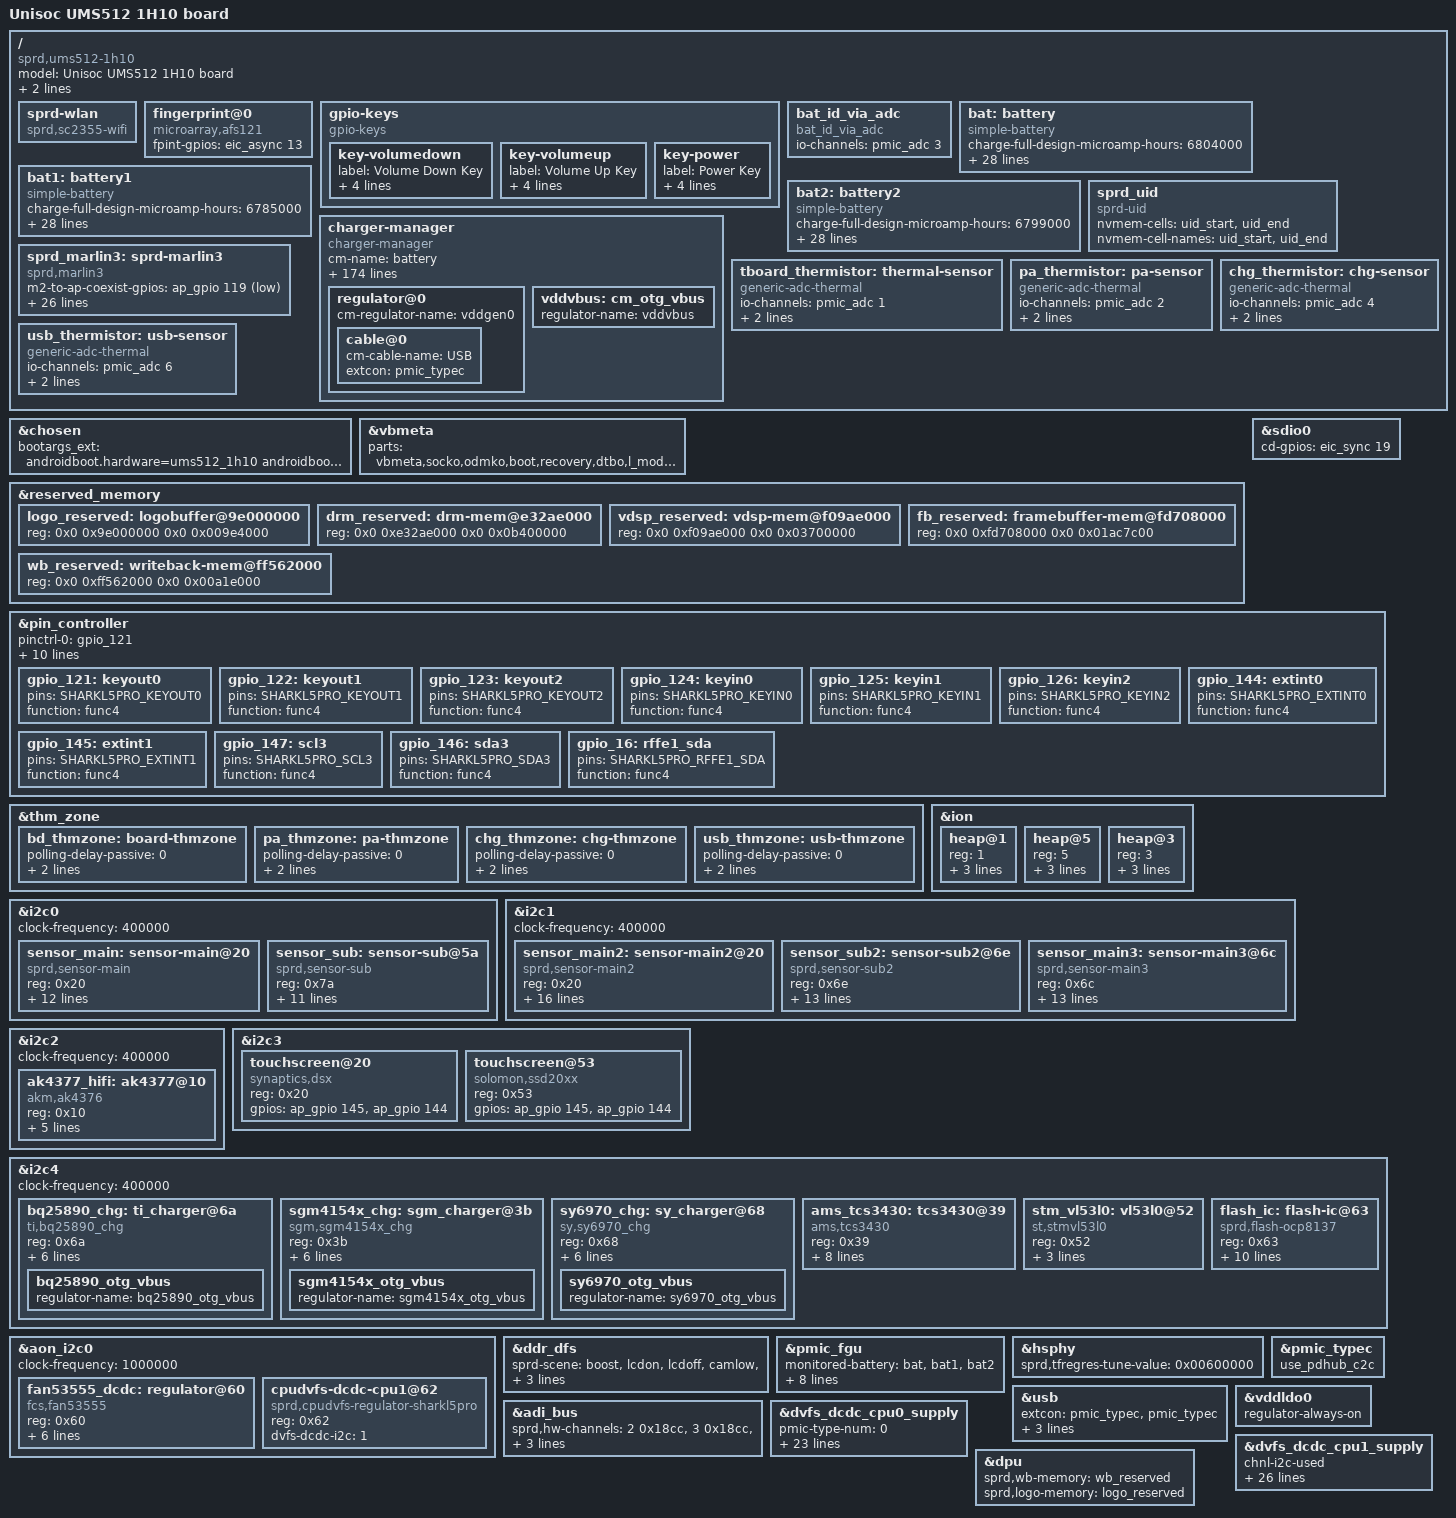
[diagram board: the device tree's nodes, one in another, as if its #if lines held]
/dts-v1/;
/plugin/;

#include <dt-bindings/input/input.h>
#include <dt-bindings/gpio/gpio.h>
#include <dt-bindings/interrupt-controller/arm-gic.h>
#include <dt-bindings/clock/sprd,sharkl5pro-clk.h>
#include <dt-bindings/mfd/sprd,sc2730-regs.h>
#include <dt-bindings/mfd/sprd,sc2730-mask.h>
#include <dt-bindings/wdv/wdv.h>

/ {

	model = "Unisoc UMS512 1H10 board";
	compatible = "sprd,ums512-1h10";
	sprd,sc-id = "ums512 1h10 1000";
	sprd,board_id = <0x1100>; //XX00:base board,XX00~XXFF:customize board

	fragment {
		target-path = "/";
		__overlay__ {
			sprd-wlan {
				compatible = "sprd,sc2355-wifi";
			};

			fingerprint@0 {
				compatible = "microarray,afs121";
				fpint-gpios = <&eic_async 13 0>;
			};

			gpio-keys {
				compatible = "gpio-keys";
				/*Tab A8 code for SR-AX6300-01-23 by fengzhigang at 2021/08/04 start*/
				key-volumedown {
					label = "Volume Down Key";
					linux,code = <KEY_VOLUMEDOWN>;
					gpios = <&pmic_eic 4 GPIO_ACTIVE_HIGH>;
					debounce-interval = <2>;
					wakeup-source;
				};

				key-volumeup {
					label = "Volume Up Key";
					linux,code = <KEY_VOLUMEUP>;
					gpios = <&ap_gpio 125 GPIO_ACTIVE_LOW>;
					debounce-interval = <2>;
					wakeup-source;
				};
				/*Tab A8 code for SR-AX6300-01-23 by fengzhigang at 2021/08/04 end*/
				key-power {
					label = "Power Key";
					linux,code = <KEY_POWER>;
					gpios = <&pmic_eic 1 GPIO_ACTIVE_LOW>;
					debounce-interval = <2>;
					wakeup-source;
				};
			};
			/* Tab A8 code for AX6300DEV-11 by wenyaqi at 20210730 start */
			bat_id_via_adc: bat_id_via_adc {
				compatible = "bat_id_via_adc";
				io-channels = <&pmic_adc 3>;
				io-channel-names = "customer_bat_id";
			};
			/* Tab A8 code for AX6300DEV-11 by wenyaqi at 20210730 end */

			/* Tab A8 code for SR-AX6300-01-106 by zhangyanlong at 20210903 start */
			/* Tab A8 code for SR-AX6300-01-107 by zhangyanlong at 20210830 start */
			/* Tab A8 code for AX6300DEV-11 by wenyaqi at 20210730 start */
			bat: battery {
				compatible = "simple-battery";
				charge-full-design-microamp-hours = <6804000>;
				charge-term-current-microamp = <64000>;
				constant_charge_voltage_max_microvolt = <4400000>;
				factory-internal-resistance-micro-ohms = <120000>;
				voltage-min-design-microvolt = <3456000>;
				ocv-capacity-celsius = <20>;
				ocv-capacity-table-0 = <4354000 100>, <4293000 95>, <4236000 90>,
							<4180000 85>, <4126000 80>, <4075000 75>,
							<4027000 70>, <3985000 65>, <3942000 60>,
							<3887000 55>, <3854000 50>, <3830000 45>,
							<3811000 40>, <3796000 35>, <3782000 30>,
							<3765000 25>, <3746000 20>, <3722000 15>,
							<3693000 10>, <3681000 5>, <3400000 0>;
				voltage-temp-table = <1092000 800>, <984000 850>, <878000 900>,
							  <776000 950>, <679000 1000>, <591000 1050>,
							  <511000 1100>, <441000 1150>, <379000 1200>,
							  <325000 1250>, <278000 1300>, <238000 1350>,
							  <204000 1400>, <175000 1450>, <150000 1500>,
							  <129000 1550>, <112000 1600>, <97000 1650>,
							  <84000 1700>, <73000 1750>, <63000 1800>,
							  <55000 1850>;
				capacity-temp-table = <45 99>, <25 100>, <10 100>, <0 98>, <(-10) 91>, <(-20) 75>;
				resistance-temp-table = <45 88>, <25 100>, <10 156>, <0 541>, <(-10) 683>, <(-20) 756>;
				charge-sdp-current-microamp = <500000 500000>;
				/* Tab A8 code for AX6300DEV-11 by wenyaqi at 20210730 start */
				// charge-dcp-current-microamp = <2000000 3000000>;
				charge-dcp-current-microamp = <2000000 1550000>;
				/* Tab A8 code for AX6300DEV-11 by wenyaqi at 20210730 end */
				charge-cdp-current-microamp = <1150000 1150000>;
				charge-unknown-current-microamp = <500000 500000>;
			};
			/* Tab A8 code for SR-AX6300-01-107 by zhangyanlong at 20210830 end */

			bat1: battery1 {
				compatible = "simple-battery";
				charge-full-design-microamp-hours = <6785000>;
				charge-term-current-microamp = <640000>;
				constant_charge_voltage_max_microvolt = <4400000>;
				factory-internal-resistance-micro-ohms = <116000>;
				voltage-min-design-microvolt = <3456000>;
				ocv-capacity-celsius = <20>;
				ocv-capacity-table-0 = <4357000 100>, <4297000 95>, <4239000 90>,
							<4182000 85>, <4128000 80>, <4076000 75>,
							<4028000 70>, <3985000 65>, <3944000 60>,
							<3885000 55>, <3854000 50>, <3830000 45>,
							<3811000 40>, <3796000 35>, <3783000 30>,
							<3765000 25>, <3746000 20>, <3722000 15>,
							<3693000 10>, <3680000 5>, <3400000 0>;
				voltage-temp-table = <1109000 800>, <998000 850>, <889000 900>,
							  <784000 950>, <685000 1000>, <595000 1050>,
							  <514000 1100>, <442000 1150>, <379000 1200>,
							  <325000 1250>, <270000 1300>, <238000 1350>,
							  <204000 1400>, <175000 1450>, <151000 1500>,
							  <130000 1550>, <112000 1600>, <97000 1650>,
							  <84000 1700>, <73000 1750>, <64000 1800>,
							  <55000 1850>;
				capacity-temp-table = <45 99>, <25 100>, <10 100>, <0 98>, <(-10) 90>, <(-20) 73>;
				resistance-temp-table = <45 67>, <25 100>, <10 371>, <0 609>, <(-10) 718>, <(-20) 794>;
				charge-sdp-current-microamp = <500000 500000>;
				/* Tab A8 code for AX6300DEV-11 by wenyaqi at 20210730 start */
				// charge-dcp-current-microamp = <2000000 3000000>;
				charge-dcp-current-microamp = <2000000 1550000>;
				/* Tab A8 code for AX6300DEV-11 by wenyaqi at 20210730 end */
				charge-cdp-current-microamp = <1150000 1150000>;
				charge-unknown-current-microamp = <500000 500000>;
			};

			/* Tab A8 code for AX6300DEV-114 by zhangyanlong at 20210901 start */
			bat2: battery2 {
				compatible = "simple-battery";
				charge-full-design-microamp-hours = <6799000>;
				charge-term-current-microamp = <640000>;
				constant_charge_voltage_max_microvolt = <4400000>;
				factory-internal-resistance-micro-ohms = <101000>;
				voltage-min-design-microvolt = <3456000>;
				ocv-capacity-celsius = <20>;
				ocv-capacity-table-0 = <4350000 100>, <4293000 95>, <4236000 90>,
							<4180000 85>, <4126000 80>, <4075000 75>,
							<4027000 70>, <3984000 65>, <3941000 60>,
							<3887000 55>, <3854000 50>, <3830000 45>,
							<3810000 40>, <3795000 35>, <3781000 30>,
							<3762000 25>, <3743000 20>, <3719000 15>,
							<3691000 10>, <3680000 5>, <3400000 0>;
				voltage-temp-table = <1109000 800>, <998000 850>, <889000 900>,
							  <784000 950>, <685000 1000>, <595000 1050>,
							  <514000 1100>, <442000 1150>, <379000 1200>,
							  <325000 1250>, <270000 1300>, <238000 1350>,
							  <204000 1400>, <175000 1450>, <151000 1500>,
							  <130000 1550>, <112000 1600>, <97000 1650>,
							  <84000 1700>, <73000 1750>, <64000 1800>,
							  <55000 1850>;
				capacity-temp-table = <45 99>, <25 100>, <10 100>, <0 99>, <(-10) 92>, <(-20) 80>;
				resistance-temp-table = <45 87>, <25 100>, <10 249>, <0 857>, <(-10) 1184>, <(-20) 1311>;
				charge-sdp-current-microamp = <500000 500000>;
				/* Tab A8 code for AX6300DEV-11 by wenyaqi at 20210730 start */
				// charge-dcp-current-microamp = <2000000 3000000>;
				charge-dcp-current-microamp = <2000000 1550000>;
				/* Tab A8 code for AX6300DEV-11 by wenyaqi at 20210730 end */
				charge-cdp-current-microamp = <1150000 1150000>;
				charge-unknown-current-microamp = <500000 500000>;
			};
			/* Tab A8 code for AX6300DEV-114 by zhangyanlong at 20210901 end */
			/* Tab A8 code for SR-AX6300-01-106 by zhangyanlong at 20210903 end */

			charger-manager {
				compatible = "charger-manager";
				cm-name = "battery";
				cm-poll-mode = <2>;
				cm-poll-interval = <15000>;
				cm-battery-stat = <2>;

				/* Tab A8 code for SR-AX6300-01-4 by zhangyanlong at 20210820 start */
				draw-vbus-gpio = <&ap_gpio 137 GPIO_ACTIVE_LOW>;
				io-channels = <&pmic_adc 6>;
				io-channel-names = "customer_usb_ntc";
				/* Tab A8 code for SR-AX6300-01-4 by zhangyanlong at 20210820 end */
				cm-fullbatt-vchkdrop-ms = <30000>;
				/* Tab A8 code for SR-AX6300-01-176 by qiaodan at 20210816 start */
				cm-fullbatt-vchkdrop-volt = <35000>;
				cm-fullbatt-voltage = <4395000>;
				cm-first-fullbatt-current = <280000>;
				cm-fullbatt-current = <180000>;
				/* Tab A8 code for SR-AX6300-01-176 by qiaodan at 20210816 end */
				cm-fullbatt-capacity = <100>;

				/* Tab A8 code for AX6300DEV-11 by wenyaqi at 20210730 start */
				cm-num-power-supplys = <3>;    // numbers of Charger IC
				/* Tab A8 code for AX6300DEV-11 by wenyaqi at 20210730 end */
				cm-chargers = "fan54015_charger";
				/* Tab A8 code for SR-AX6300-01-102 by wenyaqi at 20210808 start */
				cm-power-supplys = "bq25890_charger", "sgm4154x_charger", "sy6970_charger";
				// cm-power-supplys = "fan54015_charger", "sgm4154x_charger", "sy6970_charger";
				/* Tab A8 code for SR-AX6300-01-102 by wenyaqi at 20210808 end */
				cm-fuel-gauge = "sc27xx-fgu";

				/* in deci centigrade */
				/* Tab A8 code for AX6300DEV-11 by wenyaqi at 20210730 start */
				// cm-battery-cold = <200>;
				cm-battery-cold = <0>;
				cm-battery-cold-in-minus;
				// cm-battery-hot = <800>;
				cm-battery-hot = <500>;
				// cm-battery-temp-diff = <100>;
				cm-battery-temp-diff = <30>;
				/* Tab A8 code for AX6300DEV-11 by wenyaqi at 20210730 start */

				/* Allow charging for 6hr */
				cm-charging-max = <21600000>;
				/* recovery charging after stop charging 45min */
				cm-discharging-max = <2700000>;

				/* the interval to feed charger watchdog */
				cm-wdt-interval = <60>;

				/* drop voltage in microVolts to allow shutdown */
				cm-shutdown-voltage = <3100000>;

				/* when 99% of the time is exceeded, it will be forced to 100% */
				cm-tickle-time-out = <1500>;

				/* how much time to allow capacity change */
				cm-one-cap-time = <30>;
				/* Tab A8 code for SR-AX6300-01-102 by wenyaqi at 20210808 start */
				// cm-thermal-zone = "board-thmzone";
				/* Tab A8 code for SR-AX6300-01-102 by wenyaqi at 20210808 end */
				/* when the safe charging voltage is exceeded, stop charging */
				cm-charge-voltage-max = <6500000>;
				/* drop voltage in microVolts to restart charging */
				cm-charge-voltage-drop = <700000>;
				/* Tab A8 code for SR-AX6300-01-176 by qiaodan at 20210816 start */
				cm-dcp-jeita-temp-table = <1000 1030 0 4200000>, <1050 1080 500000 4200000>,
					<1120 1150 1500000 4400000>, <1450 1420 2000000 4400000>, <1500 1470 2000000 4200000>;
				cm-dcp-jeita-temp-table-1 = <1000 1030 0 4200000>, <1050 1080 500000 4200000>,
					<1120 1150 1500000 4400000>, <1450 1420 2000000 4400000>, <1500 1470 2000000 4200000>;
				cm-dcp-jeita-temp-table-2 = <1000 1030 0 4200000>, <1050 1080 500000 4200000>,
					<1120 1150 1500000 4400000>, <1450 1420 2000000 4400000>, <1500 1470 2000000 4200000>;
				cm-sdp-jeita-temp-table = <1000 1030 0 4200000>, <1050 1080 500000 4200000>,
					<1120 1150 540000 4400000>, <1450 1420 540000 4400000>, <1500 1470 540000 4200000>;
				cm-sdp-jeita-temp-table-1 = <1000 1030 0 4200000>, <1050 1080 500000 4200000>,
					<1120 1150 540000 4400000>, <1450 1420 540000 4400000>, <1500 1470 540000 4200000>;
				cm-sdp-jeita-temp-table-2 = <1000 1030 0 4200000>, <1050 1080 500000 4200000>,
					<1120 1150 540000 4400000>, <1450 1420 540000 4400000>, <1500 1470 540000 4200000>;
				cm-cdp-jeita-temp-table = <1000 1030 0 4200000>, <1050 1080 500000 4200000>,
					<1120 1150 1500000 4400000>, <1450 1420 1500000 4400000>, <1500 1470 1500000 4200000>;
				cm-cdp-jeita-temp-table-1 = <1000 1030 0 4200000>, <1050 1080 500000 4200000>,
					<1120 1150 1500000 4400000>, <1450 1420 1500000 4400000>, <1500 1470 1500000 4200000>;
				cm-cdp-jeita-temp-table-2= <1000 1030 0 4200000>, <1050 1080 500000 4200000>,
					<1120 1150 1500000 4400000>, <1450 1420 1500000 4400000>, <1500 1470 1500000 4200000>;
				cm-unknown-jeita-temp-table = <1000 1030 0 4200000>, <1050 1080 500000 4200000>,
					<1120 1150 540000 4400000>, <1450 1420 540000 4400000>, <1500 1470 540000 4200000>;
				cm-unknown-jeita-temp-table-1 = <1000 1030 0 4200000>, <1050 1080 500000 4200000>,
					<1120 1150 540000 4400000>, <1450 1420 540000 4400000>, <1500 1470 540000 4200000>;
				cm-unknown-jeita-temp-table-2 = <1000 1030 0 4200000>, <1050 1080 500000 4200000>,
					<1120 1150 540000 4400000>, <1450 1420 540000 4400000>, <1500 1470 540000 4200000>;
				cm-fchg-jeita-temp-table = <1000 1030 0 4200000>, <1050 1080 500000 4200000>,
					<1120 1150 1500000 4400000>, <1450 1420 2700000 4400000>, <1500 1470 2700000 4200000>;
				cm-fchg-jeita-temp-table-1 = <1000 1030 0 4200000>, <1050 1080 500000 4200000>,
					<1120 1150 1500000 4400000>, <1450 1420 2700000 4400000>, <1500 1470 2700000 4200000>;
				cm-fchg-jeita-temp-table-2 = <1000 1030 0 4200000>, <1050 1080 500000 4200000>,
					<1120 1150 1500000 4400000>, <1450 1420 2700000 4400000>, <1500 1470 2700000 4200000>;
				cm-flash-jeita-temp-table = <1000 1030 0 4200000>, <1050 1080 500000 4200000>,
					<1120 1150 1500000 4400000>, <1450 1420 2000000 4400000>, <1500 1470 2000000 4200000>;
				cm-flash-jeita-temp-table-1 = <1000 1030 0 4200000>, <1050 1080 500000 4200000>,
					<1120 1150 1500000 4400000>, <1450 1420 2000000 4400000>, <1500 1470 2000000 4200000>;
				cm-flash-jeita-temp-table-2 = <1000 1030 0 4200000>, <1050 1080 500000 4200000>,
					<1120 1150 1500000 4400000>, <1450 1420 2000000 4400000>, <1500 1470 2000000 4200000>;
				cm-wl-bpp-jeita-temp-table = <1000 1030 0 4200000>, <1050 1080 500000 4200000>,
					<1120 1150 1000000 4400000>, <1450 1420 1000000 4400000>, <1500 1470 1000000 4200000>;
				cm-wl-bpp-jeita-temp-table-1 = <1000 1030 0 4200000>, <1050 1080 500000 4200000>,
					<1120 1150 1000000 4400000>, <1450 1420 1000000 4400000>, <1500 1470 1000000 4200000>;
				cm-wl-bpp-jeita-temp-table-2 = <1000 1030 0 4200000>, <1050 1080 500000 4200000>,
					<1120 1150 1000000 4400000>, <1450 1420 1000000 4400000>, <1500 1470 1000000 4200000>;
				cm-wl-epp-jeita-temp-table = <1000 1030 0 4200000>, <1050 1080 500000 4200000>,
					<1120 1150 1500000 4400000>, <1450 1420 2000000 4400000>, <1500 1470 2000000 4200000>;
				cm-wl-epp-jeita-temp-table-1 = <1000 1030 0 4200000>, <1050 1080 500000 4200000>,
					<1120 1150 1500000 4400000>, <1450 1420 2000000 4400000>, <1500 1470 2000000 4200000>;
				cm-wl-epp-jeita-temp-table-2 = <1000 1030 0 4200000>, <1050 1080 500000 4200000>,
					<1120 1150 1500000 4400000>, <1450 1420 2000000 4400000>, <1500 1470 2000000 4200000>;
				/* Tab A8 code for SR-AX6300-01-176 by qiaodan at 20210816 end */

				/* Tab A8 code for AX6300DEV-11 by wenyaqi at 20210730 start */
				// monitored-battery = <&bat>;
				monitored-battery = <&bat &bat1 &bat2>; // bat-ATL bat1-SCUD
				/* Tab A8 code for AX6300DEV-11 by wenyaqi at 20210730 end */
				/* Tab A8 code for SR-AX6300-01-142 by qiaodan at 20210901 start */
				ss-batt-aging-enable;
				ss-cv-ranges = <0 299 4400000
						300 399 4368000
						400 699 4352000
						700 999 4304000
						1000 9999 4272000>;
				/* Tab A8 code for SR-AX6300-01-142 by qiaodan at 20210901 end */

				cm-cap-remap-table = <1 2 3>, <2 3 2>, <98 99 2>, <99 100 3>;

				regulator@0 {
					cm-regulator-name = "vddgen0";
					cable@0 {
						cm-cable-name = "USB";
						extcon = <&pmic_typec>;
					};
				};

				/* Tab A8 code for AX6300DEV-11 by wenyaqi at 20210730 start */
				vddvbus: cm_otg_vbus {
					regulator-name = "vddvbus";
				};
				/* Tab A8 code for AX6300DEV-11 by wenyaqi at 20210730 end */
			};

			sprd_uid {
				compatible = "sprd-uid";
				nvmem-cells = <&uid_start>, <&uid_end>;
				nvmem-cell-names = "uid_start", "uid_end";
			};

			sprd_marlin3: sprd-marlin3 {
				compatible = "sprd,marlin3";
				m2-to-ap-coexist-gpios = <&ap_gpio 119 GPIO_ACTIVE_LOW>;
				m2-wakeup-ap-gpios = <&ap_gpio 32 GPIO_ACTIVE_LOW>;
				permit-ap-send-gpios = <&ap_gpio 121 GPIO_ACTIVE_LOW>;
                                /* Tab A8 code for AX6300DEV-27 by lijun at 20210810 start */
				reset-gpios = <&ap_gpio 95 GPIO_ACTIVE_LOW>;
                                /* Tab A8 code for AX6300DEV-27 by lijun at 20210810 end */
				enable-gpios = <&ap_gpio 143 GPIO_ACTIVE_LOW>;
                                /* Tab A8 code for AX6300DEV-27 by lijun at 20210810 start */
				m2-to-ap-irq-gpios = <&ap_gpio 94 GPIO_ACTIVE_LOW>;
                                /* Tab A8 code for AX6300DEV-27 by lijun at 20210810 end */
                                /* Tab A8 code for AX6300DEV-1366 by zhuxiaoming at 20211001 start */
                                xtal-26m-clk-type = "TSX";
                                /* Tab A8 code for AX6300DEV-1366 by zhuxiaoming at 20211001 end */
				avdd12-supply = <&vddwcn>;
				avdd33-supply = <&vddwifipa>;
				dcxo18-supply = <&vddsim2>;
				/* Tab code for SR-AX6300-01-193 by qiaodan at 20210809 start */
				rfcustom-supply = <&vddkpled>;
				/* Tab code for SR-AX6300-01-193 by qiaodan at 20210809 end */
				/* Tab A8 code for P211110-02599 by wangyanjie at 20211213 start */
				sdio-func-def = <3>;
				/* Tab A8 code for P211110-02599 by wangyanjie at 20211213 end */
				clock-names = "clk_32k","source","enable";
				clocks = <&aon_clk CLK_AUX0>,
					 <&ext_32k>,
					 <&aonapb_gate CLK_AUX0_EB>;

				sdhci-name = <&sdio1>;
				sprd,btwf-file-name = "/dev/block/platform/soc/soc:ap-apb/71400000.sdio/by-name/wcnmodem";
				sprd,gnss-file-name = "/dev/block/platform/soc/soc:ap-apb/71400000.sdio/by-name/gnssmodem";
				adma-tx;
				adma-rx;
				/*
				 * bound parameter:
				 * [0]:addr offset, [1]:mask, [2]:unboundval, [3]:boundval
				 */
				avdd12-parent-bound-chip = <REG_ANA_SLP_DCDC_PD_CTRL MASK_ANA_SLP_DCDCGEN1_PD_EN 0x0 MASK_ANA_SLP_DCDCGEN1_PD_EN>;
				avdd12-bound-wbreq = <REG_ANA_LDO_XTL_EN10 MASK_ANA_LDO_VDDWCN_EXT_XTL3_EN 0x0 MASK_ANA_LDO_VDDWCN_EXT_XTL3_EN>;
				avdd33-bound-wbreq = <REG_ANA_LDO_XTL_EN11 MASK_ANA_LDO_VDDWIFIPA_EXT_XTL3_EN 0x0 MASK_ANA_LDO_VDDWIFIPA_EXT_XTL3_EN>;
			};

			tboard_thermistor:thermal-sensor {
				compatible = "generic-adc-thermal";
				#thermal-sensor-cells = <0>;
				io-channels = <&pmic_adc 1>;
				io-channel-names = "sensor-channel";
				temperature-lookup-table = <    (-39742) 1131
								(-29777) 1110
								(-19480) 1074
								(-4679) 983
								10110 838
								24805 654
								44922 413
								54903 316
								64895 238
								74884 178
								84883 133
								94883 100
								104880 75
								114889 57
								124872 43 >;
			};

			/* Tab A8 code for SR-AX6300-01-109 by zhangyanlong at 20210810 start */
			pa_thermistor:pa-sensor {
				compatible = "generic-adc-thermal";
				#thermal-sensor-cells = <0>;
				io-channels = <&pmic_adc 2>;
				io-channel-names = "sensor-channel";
				temperature-lookup-table = <    (-39742) 1131
								(-29777) 1110
								(-19480) 1074
								(-4679) 983
								10110 838
								24805 654
								44922 413
								54903 316
								64895 238
								74884 178
								84883 133
								94883 100
								104880 75
								114889 57
								124872 43 >;
			};

			chg_thermistor:chg-sensor {
				compatible = "generic-adc-thermal";
				#thermal-sensor-cells = <0>;
				io-channels = <&pmic_adc 4>;
				io-channel-names = "sensor-channel";
				temperature-lookup-table = <    (-39742) 1131
								(-29777) 1110
								(-19480) 1074
								(-4679) 983
								10110 838
								24805 654
								44922 413
								54903 316
								64895 238
								74884 178
								84883 133
								94883 100
								104880 75
								114889 57
								124872 43 >;
			};

			usb_thermistor:usb-sensor {
				compatible = "generic-adc-thermal";
				#thermal-sensor-cells = <0>;
				io-channels = <&pmic_adc 6>;
				io-channel-names = "sensor-channel";
				temperature-lookup-table = <    (-39742) 1131
								(-29777) 1110
								(-19480) 1074
								(-4679) 983
								10110 838
								24805 654
								44922 413
								54903 316
								64895 238
								74884 178
								84883 133
								94883 100
								104880 75
								114889 57
								124872 43 >;
			};
			/* Tab A8 code for SR-AX6300-01-109 by zhangyanlong at 20210810 end */
		};
	};
};

&chosen {
	bootargs_ext = "androidboot.hardware=ums512_1h10 androidboot.dtbo_idx=0";
};

&vbmeta {
	parts = "vbmeta,socko,odmko,boot,recovery,dtbo,l_modem,pm_sys,l_ldsp,l_gdsp,l_agdsp";
};

&reserved_memory {

	logo_reserved: logobuffer@9e000000{
		reg = <0x0 0x9e000000 0x0 0x009e4000>;
	};

#ifdef BSP_KERNEL_CONFIG_WIDEVINE_L1
	drm_reserved: drm-mem@e32ae000 {
                /*Tab A8 code for P210929-01927 by ZhangLirong at 2021/10/11 start*/
		reg = <0x0 0xe32ae000 0x0 0x0b400000>;
                /*Tab A8 code for P210929-01927 by ZhangLirong at 2021/10/11 end*/
	};
#endif

/* HS03 code for SR-SL6215-01-755 by bianxiaoqiang at 2021/10/26 start */
/*
	fd_reserved: faceid-mem@efaae000 {
		reg = <0x0 0xefaae000 0x0 0x00500000>;
	};
*/
/* HS03 code for SR-SL6215-01-755 by bianxiaoqiang at 2021/10/26 end */

	vdsp_reserved: vdsp-mem@f09ae000 {
		reg = <0x0 0xf09ae000 0x0 0x03700000>;
	};
/*
	gpu_reserved: gpu-mem@fb8ae000 {
		reg = <0x0 0xfb8ae000 0x0 0x01e5a000>;
	};
*/

	fb_reserved: framebuffer-mem@fd708000 {
                /*Tab A8 code for P210929-01927 by ZhangLirong at 2021/10/11 start*/
		reg = <0x0 0xfd708000 0x0 0x01ac7c00>;
                /*Tab A8 code for P210929-01927 by ZhangLirong at 2021/10/11 end*/
	};

	wb_reserved: writeback-mem@ff562000 {
		reg = <0x0 0xff562000 0x0 0x00a1e000>;
	};

};

&sdio0 {
	cd-gpios = <&eic_sync 19 GPIO_ACTIVE_HIGH>;
};

&pin_controller {
	pinctrl-names =
	/* keyout0 ~ keyout2 */
	"gpio_121", "gpio_122", "gpio_123",
	/* keyin0 ~ keyin2 */
	"gpio_124", "gpio_125", "gpio_126",
	/* extint0, extint1, scl3, sda3, sda */
	"gpio_144", "gpio_145", "gpio_146", "gpio_147", "gpio_16";

	pinctrl-0 = <&gpio_121>;
	pinctrl-1 = <&gpio_122>;
	pinctrl-2 = <&gpio_123>;
	pinctrl-3 = <&gpio_124>;
	pinctrl-4 = <&gpio_125>;
	pinctrl-5 = <&gpio_126>;
	pinctrl-6 = <&gpio_144>;
	pinctrl-7 = <&gpio_145>;
	pinctrl-8 = <&gpio_146>;
	pinctrl-9 = <&gpio_147>;
	pinctrl-10 = <&gpio_16>;

	gpio_121: keyout0 {
		pins = "SHARKL5PRO_KEYOUT0";
		function = "func4";
	};

	gpio_122: keyout1 {
		pins = "SHARKL5PRO_KEYOUT1";
		function = "func4";
	};

	gpio_123: keyout2 {
		pins = "SHARKL5PRO_KEYOUT2";
		function = "func4";
	};

	gpio_124: keyin0 {
		pins = "SHARKL5PRO_KEYIN0";
		function = "func4";
	};

	gpio_125: keyin1 {
		pins = "SHARKL5PRO_KEYIN1";
		function = "func4";
	};

	gpio_126: keyin2 {
		pins = "SHARKL5PRO_KEYIN2";
		function = "func4";
	};

	gpio_144: extint0 {
		pins = "SHARKL5PRO_EXTINT0";
		function = "func4";
	};

	gpio_145: extint1 {
		pins = "SHARKL5PRO_EXTINT1";
		function = "func4";
	};

	gpio_147: scl3 {
		pins = "SHARKL5PRO_SCL3";
		function = "func4";
	};

	gpio_146: sda3 {
		pins = "SHARKL5PRO_SDA3";
		function = "func4";
	};

	gpio_16: rffe1_sda {
		pins = "SHARKL5PRO_RFFE1_SDA";
		function = "func4";
	};
};

&thm_zone {
	bd_thmzone: board-thmzone {
		polling-delay-passive = <0>;
		polling-delay = <0>;
		thermal-sensors = <&tboard_thermistor>;
	};

	/* Tab A8 code for SR-AX6300-01-109 by zhangyanlong at 20210810 start */
	pa_thmzone: pa-thmzone {
		polling-delay-passive = <0>;
		polling-delay = <0>;
		thermal-sensors = <&pa_thermistor>;
	};

	chg_thmzone: chg-thmzone {
		polling-delay-passive = <0>;
		polling-delay = <0>;
		thermal-sensors = <&chg_thermistor>;
	};

	usb_thmzone: usb-thmzone {
		polling-delay-passive = <0>;
		polling-delay = <0>;
		thermal-sensors = <&usb_thermistor>;
	};
	/* Tab A8 code for SR-AX6300-01-109 by zhangyanlong at 20210810 end */
};

&ion {
#ifdef BSP_KERNEL_CONFIG_WIDEVINE_L1
	heap@1 {
		reg = <1>;
		label = "carveout_mm";
		type = <2>;
		memory-region = <&drm_reserved>;
	};
#endif

/* HS03 code for SR-SL6215-01-755 by bianxiaoqiang at 2021/10/26 start */
/*
	heap@4 {
		reg = <4>;
		label = "carveout_fd";
		type = <2>;
		memory-region = <&fd_reserved>;
	};
*/
/* HS03 code for SR-SL6215-01-755 by bianxiaoqiang at 2021/10/26 end */

	heap@5 {
		reg = <5>;
		label = "carveout_vdsp";
		type = <2>;
		memory-region = <&vdsp_reserved>;
	};
};

&i2c0 {
	status = "okay";
	clock-frequency = <400000>;

	sensor_main: sensor-main@20 {
		compatible = "sprd,sensor-main";
		reg = <0x20>;
		clock-names = "clk_src","sensor_eb",
			"clk_96m","clk_76m8",
			"clk_48m","clk_26m";
		clocks = <&mm_clk CLK_SENSOR0>,<&mm_gate CLK_MM_SENSOR0_EB>,
				<&pll2 CLK_TWPLL_96M>,<&pll2 CLK_TWPLL_76M8>,
				<&pll2 CLK_TWPLL_48M>,<&ext_26m>;
		vddio-supply = <&vddcamio>;
		vddcama-supply = <&vddcama0>;
		vddcamd-supply = <&vddcamd0>;
		vddcammot-supply = <&vddcammot>;
		reset-gpios = <&ap_gpio 44 0>;
		power-down-gpios = <&ap_gpio 46 0>;
		sprd,phyid = <0>;
		csi = <&csi0>;
	};
/*Tab A8  code for AX6300DEV-13 by wuwenjie at 20210802 start*/
	sensor_sub: sensor-sub@5a {
		compatible = "sprd,sensor-sub";
		reg = <0x7a>;
		clock-names = "clk_src","sensor_eb",
			"clk_96m","clk_76m8",
			"clk_48m","clk_26m";
		clocks = <&mm_clk CLK_SENSOR1>,<&mm_gate CLK_MM_SENSOR1_EB>,
				<&pll2 CLK_TWPLL_96M>,<&pll2 CLK_TWPLL_76M8>,
				<&pll2 CLK_TWPLL_48M>,<&ext_26m>;
		vddio-supply = <&vddcamio>;
		vddcama-supply = <&vddcama1>;
		vddcamd-supply = <&vddcamd1>;
		vddcammot-supply = <&vddcammot>;
		reset-gpios = <&ap_gpio 45 0>;
		sprd,phyid = <2>;
		csi = <&csi1>;
	};
/*Tab A8  code for AX6300DEV-13 by wuwenjie at 20210802 end*/
};

&i2c1 {
	status = "okay";
	clock-frequency = <400000>;

	sensor_main2: sensor-main2@20 {
		compatible = "sprd,sensor-main2";
		reg = <0x20>;
		clock-names = "clk_src","sensor_eb",
			"clk_96m","clk_76m8",
			"clk_48m","clk_26m";
		clocks = <&mm_clk CLK_SENSOR1>,<&mm_gate CLK_MM_SENSOR1_EB>,
				<&pll2 CLK_TWPLL_96M>,<&pll2 CLK_TWPLL_76M8>,
				<&pll2 CLK_TWPLL_48M>,<&ext_26m>;
		vddio-supply = <&vddcamio>;
		vddcama-supply = <&vddcama1>;
		vddcamd-supply = <&vddcamd1>;
		vddcammot-supply = <&vddcammot>;
		avdd-gpios = <&ap_gpio 33 0>;
		mot-gpios = <&ap_gpio 88 0>;
		reset-gpios = <&ap_gpio 45 0>;
		power-down-gpios = <&ap_gpio 47 0>;
		mipi-switch-en-gpios = <&ap_gpio 55 0>;
		mipi-switch-mode-gpios = <&ap_gpio 8 0>;
		sprd,phyid = <1>;
		csi = <&csi1>;
	};

	sensor_sub2: sensor-sub2@6e {
		compatible = "sprd,sensor-sub2";
		reg = <0x6e>;
		clock-names = "clk_src","sensor_eb",
			"clk_96m","clk_76m8",
			"clk_48m","clk_26m";
		clocks = <&mm_clk CLK_SENSOR1>,<&mm_gate CLK_MM_SENSOR1_EB>,
			<&pll2 CLK_TWPLL_96M>,<&pll2 CLK_TWPLL_76M8>,
			<&pll2 CLK_TWPLL_48M>,<&ext_26m>;
		vddio-supply = <&vddcamio>;
		vddcama-supply = <&vddcama1>;
		vddcamd-supply = <&vddcamd1>;
		vddcammot-supply = <&vddcammot>;
		mot-gpios = <&ap_gpio 88 0>;
		reset-gpios = <&ap_gpio 41 0>;
		power-down-gpios = <&ap_gpio 40 0>;
		sprd,phyid = <2>;
		csi = <&csi2>;
	};

	sensor_main3: sensor-main3@6c {
		compatible = "sprd,sensor-main3";
		reg = <0x6c>;
		clock-names = "clk_src","sensor_eb",
			"clk_96m","clk_76m8",
			"clk_48m","clk_26m";
		clocks = <&mm_clk CLK_SENSOR1>,<&mm_gate CLK_MM_SENSOR1_EB>,
				<&pll2 CLK_TWPLL_96M>,<&pll2 CLK_TWPLL_76M8>,
				<&pll2 CLK_TWPLL_48M>,<&ext_26m>;
		vddio-supply = <&vddcamio>;
		vddcama-supply = <&vddcama1>;
		vddcamd-supply = <&vddcamd1>;
		vddcammot-supply = <&vddcammot>;
		mot-gpios = <&ap_gpio 88 0>;
		reset-gpios = <&ap_gpio 41 0>;
		power-down-gpios = <&ap_gpio 40 0>;
		sprd,phyid = <2>;
		csi = <&csi2>;
	};
};

&i2c2 {
	status = "okay";
	clock-frequency = <400000>;

	ak4377_hifi: ak4377@10 {
		compatible = "akm,ak4376";
		reg = <0x10>;
		#sound-dai-cells = <1>;
		vddldo1-supply = <&vddldo1>;
		sprd,vddldo1-voltage = <1800000>;
		ak4377,pdn-gpio = <&ap_gpio 116 GPIO_ACTIVE_HIGH>;

		clock-names = "clk_48M", "source", "enable";
		clocks = <&aon_clk CLK_AUX1>,
			 <&pll2 CLK_TWPLL_19M2>,
			 <&aonapb_gate CLK_AUX1_EB>;
	};
};

&i2c3 {
	status = "okay";

	touchscreen@20 {
		compatible = "synaptics,dsx";
		reg = <0x20>;
		gpios = <&ap_gpio 145 GPIO_ACTIVE_HIGH
			&ap_gpio 144 GPIO_ACTIVE_HIGH>;
	};

	touchscreen@53 {
		compatible = "solomon,ssd20xx";
		reg = <0x53>;
		gpios = <&ap_gpio 145 GPIO_ACTIVE_HIGH
			&ap_gpio 144 GPIO_ACTIVE_HIGH>;
	};

};

&i2c4 {
	status = "okay";
	/* Tab A8 code for SR-AX6300-01-103 by qiaodan at 20210812 start */
	clock-frequency = <400000>;
	/* Tab A8 code for SR-AX6300-01-103 by qiaodan at 20210812 end */
/* Tab A8 code for AX6300DEV-11 by wenyaqi at 20210730 start */
/* Tab A8 code for SR-AX6300-01-102 by wenyaqi at 20210808 start */
/*
	fan54015_chg: charger@6a {
		compatible = "fairchild,fan54015_chg";
		reg = <0x6a>;
		phys = <&hsphy>;
		monitored-battery = <&bat>;
		extcon = <&pmic_typec>;
		fan54015_otg_vbus: fan54015_otg_vbus {
			regulator-name = "fan54015_otg_vbus";
		};
	};
*/
	bq25890_chg: ti_charger@6a {
		compatible = "ti,bq25890_chg";
		reg = <0x6a>;
		phys = <&hsphy>;
		monitored-battery = <&bat &bat1 &bat2>; // bat-ATL bat1-SCUD
		extcon = <&pmic_typec>, <&pmic_pd>;
		pd-extcon-enable;
		/* Tab A8 code for AX6300DEV-2368 by qiaodan at 20211028 start */
		use-typec-extcon;
		/* Tab A8 code for AX6300DEV-2368 by qiaodan at 20211028 end */
		irq-gpio = <&ap_gpio 156 GPIO_ACTIVE_LOW>;
		bq25890_otg_vbus: bq25890_otg_vbus {
			regulator-name = "bq25890_otg_vbus";
		};
	};
/* Tab A8 code for SR-AX6300-01-102 by wenyaqi at 20210808 end */
	/* Tab A8 code for SR-AX6300-01-103 by qiaodan at 20210812 start */
	sgm4154x_chg: sgm_charger@3b {
		compatible = "sgm,sgm4154x_chg";
		reg = <0x3b>;
		phys = <&hsphy>;
		monitored-battery = <&bat &bat1 &bat2>; // bat-ATL bat1-SCUD
		/* Tab A8 code for AX6300DEV-2368 by qiaodan at 20211028 start */
		extcon = <&pmic_typec>, <&pmic_pd>;
		pd-extcon-enable;
		use-typec-extcon;
		/* Tab A8 code for AX6300DEV-2368 by qiaodan at 20211028 end */
		irq-gpio = <&ap_gpio 156 GPIO_ACTIVE_LOW>;
		sgm4154x_otg_vbus: sgm4154x_otg_vbus {
			regulator-name = "sgm4154x_otg_vbus";
		};
	};
	/* Tab A8 code for SR-AX6300-01-103 by qiaodan at 20210812 end */
	sy6970_chg: sy_charger@68 {
		compatible = "sy,sy6970_chg";
		reg = <0x68>;
		phys = <&hsphy>;
		monitored-battery = <&bat &bat1 &bat2>; // bat-ATL bat1-SCUD
		/* Tab A8 code for AX6300DEV-2368 by qiaodan at 20211028 start */
		extcon = <&pmic_typec>, <&pmic_pd>;
		pd-extcon-enable;
		use-typec-extcon;
		/* Tab A8 code for AX6300DEV-2368 by qiaodan at 20211028 end */
		irq-gpio = <&ap_gpio 156 GPIO_ACTIVE_LOW>;
		sy6970_otg_vbus: sy6970_otg_vbus {
			regulator-name = "sy6970_otg_vbus";
		};
	};
	/* Tab A8 code for AX6300DEV-11 by wenyaqi at 20210730 end */

	ams_tcs3430: tcs3430@39 {
		compatible = "ams,tcs3430";
		reg = <0x39>;
		als_name = "ams_als";
		persist = <0>;
		als_time_ms = <100>;
		als_gain = <64>;
		int_config = <0>;
		als_can_wake = <1>;
		irq_gpios = <112>;
		interrupt-parent = <&ap_gpio>;
		//interrupts = <112 IRQ_TYPE_LEVEL_LOW>;
	};

	stm_vl53l0: vl53l0@52 {
		compatible = "st,stmvl53l0";
		reg = <0x52>;
		reset_gpios = <86>;
		irq_gpios = <87>;
		interrupt-parent = <&ap_gpio>;
		//interrupts = <87 IRQ_TYPE_LEVEL_LOW>;
	};
/*Tab A8  code for AX6300DEV-13 by wuwenjie at 20210810 start*/
	flash_ic: flash-ic@63 {
		compatible = "sprd,flash-ocp8137";
		reg = <0x63>;
		sprd,flash-ic = <8137>;
		sprd,torch = <1>;
		sprd,preflash = <1>;
		sprd,highlight = <1>;
		sprd,torch-level = <128>;
		sprd,preflash-level = <128>;
		sprd,highlight-level = <128>;
		sprd,lvfm-enable = <1>;
		flash-chip-en-gpios = <&ap_gpio 136 0>;
		flash-en-gpios = <&ap_gpio 137 0>;
	};
/*Tab A8  code for AX6300DEV-13 by wuwenjie at 20210810 end*/

};

&aon_i2c0 {
	status = "okay";
	clock-frequency = <1000000>;

	fan53555_dcdc: regulator@60 {
		compatible = "fcs,fan53555";
		reg = <0x60>;
		regulator-name = "fan53555";
		regulator-min-microvolt = <600000>;
		regulator-max-microvolt = <1230000>;
		regulator-ramp-delay = <64000>;
		regulator-always-on;
		fcs,suspend-voltage-selector = <1>;
	};

	/* A virtual i2c device */
	cpudvfs-dcdc-cpu1@62{
		compatible = "sprd,cpudvfs-regulator-sharkl5pro";
		reg = <0x62>;
		dvfs-dcdc-i2c = <1>;
	};
};

&ddr_dfs {
	sprd-scene = "boost", "lcdon", "lcdoff", "camlow",
		"camhigh", "camveryhigh", "faceid", "inputboost";
	sprd-freq = <1333 768 256 384 512 0xbacd 1333 1333>;
};

&pmic_fgu {
	/* Tab A8 code for AX6300DEV-11 by wenyaqi at 20210730 start */
	monitored-battery = <&bat &bat1 &bat2>; // bat-ATL bat1-SCUD
	/* Tab A8 code for AX6300DEV-11 by wenyaqi at 20210730 end */
	sprd,calib-resistance-real = <10000>;
	sprd,calib-resistance-spec = <20000>;
	/* Tab A8 code for SR-AX6300-01-107 by zhangyanlong at 20210830 start */
	first-calib-voltage = <3568000>;
	/* Tab A8 code for SR-AX6300-01-107 by zhangyanlong at 20210830 end */
	first-calib-capacity = <50>;
	fgu-capacity-track;
	fullbatt-track-end-vol = <4345>;
	fullbatt-track-end-cur = <130>;
	phys = <&hsphy>;
};

/* Tab A8 code for AX6300DEV-34 by wangjian at 20210813 start */
&hsphy {
	sprd,tfregres-tune-value = <0x00600000>;
	status = "okay";
};
/* Tab A8 code for AX6300DEV-34 by wangjian at 20210813 end */
/* Tab A8 code for AX6300DEV-2368 by qiaodan at 20211028 start */
&usb {
	extcon = <&pmic_typec>, <&pmic_typec>;
	vbus-supply = <&vddvbus>;
	use_pdhub_c2c;
	use_second_charger_detct;
};

&pmic_typec {
	use_pdhub_c2c;
};

/* Tab A8 code for AX6300DEV-2368 by qiaodan at 20211028 end */
&vddldo0 {
	regulator-always-on;
};

&adi_bus {
	sprd,hw-channels = <2 0x18cc>, <3 0x18cc>, <13 0x1854>, <15 0x1874>,
			 <17 0x1844>,<19 0x1844>, <21 0x1864>, <30 0x1820>,
			 <35 0x19b8>, <39 0x19ac>, <32 0x197c>, <33 0x1988>;
};

&dvfs_dcdc_cpu0_supply {
	pmic-type-num = <0>;
	slew-rate = <9375>; /* 9375uV/us */
	top-dvfs-adi-state = <0x70 0 0xf>;
	voltage-grade-num = <7>;
	voltage-grade = <0 0xf0 0xf4 0 0x1ff>,
		<1 0xf0 0xf4 9 0x1ff>,
		<2 0x100 0xf4 18 0x1ff>,
		<3 0x110 0xf8 0 0x1ff>,
		<4 0x120 0xf8 9 0x1ff>,
		<5 0x130 0xf8 18 0x1ff>,
		<6 0x140 0xfc 0 0x1ff>;
	voltage-up-delay = <50 0x58 0 0xffff 0x600>,
		<100 0x58 16 0xffff 0xa00>,
		<150 0x54 0 0xffff 0xf00>,
		<200 0x54 16 0xffff 0x1400>,
		<250 0x50 0 0xffff 0x1900>,
		<300 0x50 16 0xffff 0x1e00>,
		<350 0x110 0 0xffff 0x2300>;
	voltage-down-delay = <50 0x64 0 0xffff 0x600>,
		<100 0x64 16 0xffff 0xa00>,
		<150 0x60 0 0xffff 0xf00>,
		<200 0x60 16 0xffff 0x1400>,
		<250 0x5c 0 0xffff 0x1900>,
		<300 0x5c 16 0xffff 0x1e00>,
		<350 0x114 0 0xffff 0x2300>;
	tuning-latency-us = <0>;
	chnl-in-i2c = <0>;
};

&dvfs_dcdc_cpu1_supply {
	chnl-i2c-used;
	third-pmic-used;
	pmic-type-num = <2>;
	slew-rate = <4000>; /* 4000uV/us */
	supply-type-sel = <0x120 0 1>;
	top-dvfs-i2c-state = <0x9c 4 0xf>;
	voltage-grade-num = <6>;
	voltage-grade = <0 0x0f 0x12c 0 0x7f>,
		<1 0x14 0x12c 7 0x7f>,
		<2 0x19 0x12c 14 0x7f>,
		<3 0x1e 0x12c 21 0x7f>,
		<4 0x23 0x130 0 0x7f>,
		<5 0x28 0x130 7 0x7f>;
	voltage-up-delay = <50 0x84 0 0xffff 0x1600>,
		<100 0x84 16 0xffff 0x1a00>,
		<150 0x80 0 0xffff 0x1f00>,
		<200 0x80 16 0xffff 0x2400>,
		<250 0x7c 0 0xffff 0x2900>,
		<300 0x7c 16 0xffff 0x2e00>,
		<350 0x118 0 0xffff 0x3300>;
	voltage-down-delay = <50 0x90 0 0xffff 0x600>,
		<100 0x90 16 0xffff 0xa00>,
		<150 0x8c 0 0xffff 0xf00>,
		<200 0x8c 16 0xffff 0x1400>,
		<250 0x88 0 0xffff 0x1900>,
		<300 0x88 16 0xffff 0x1e00>,
		<350 0x11c 0 0xffff 0x2300>;
	tuning-latency-us = <0>;
	chnl-in-i2c = <1>;
};

&ion {
	heap@3 {
		reg = <3>;
		label = "carveout_fb";
		type = <2>;
		memory-region = <&fb_reserved>;
	};
};

&dpu {
	sprd,wb-memory = <&wb_reserved>;
	sprd,logo-memory = <&logo_reserved>;
};

/* Tab A8 code for SR-SL6215-01-233/SR-SL6215-01-208 by sunxunou at 2021/08/02 start */
#include "Tab_A8/AX6300-OT10-common.dtsi"
/* Tab A8 code for SR-SL6215-01-233/SR-SL6215-01-208 by sunxunou at 2021/08/02 end*/
#include "ums512-1h10-sec-common.dtsi"
